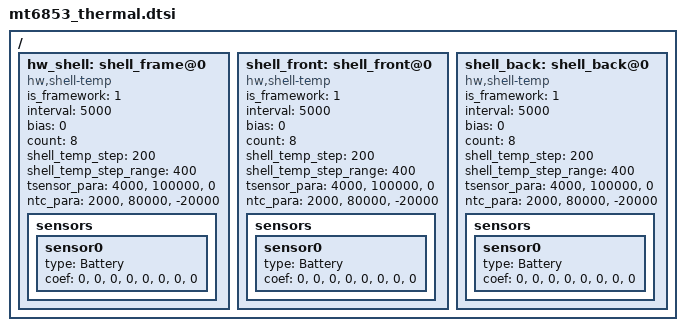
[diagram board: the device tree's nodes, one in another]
/{
	hw_shell: shell_frame@0 {
		compatible = "hw,shell-temp";
		is_framework = <1>;
		interval = <5000>;
		bias = <0>;
		count = <8>;
		shell_temp_step = <200>;
		shell_temp_step_range = <400>;
		tsensor_para = "4000","100000","0";
		ntc_para = "2000","80000","-20000";
		status = "ok";
		sensors {
			sensor0 {
				type = "Battery";
				coef = "0","0","0","0","0","0","0","0";
			};
		};
	};
	shell_front: shell_front@0 {
		compatible = "hw,shell-temp";
		is_framework = <1>;
		interval = <5000>;
		bias = <0>;
		count = <8>;
		shell_temp_step = <200>;
		shell_temp_step_range = <400>;
		tsensor_para = "4000","100000","0";
		ntc_para = "2000","80000","-20000";
		status = "ok";
		sensors {
			sensor0 {
				type = "Battery";
				coef = "0","0","0","0","0","0","0","0";
			};
		};
	};
	shell_back: shell_back@0 {
		compatible = "hw,shell-temp";
		is_framework = <1>;
		interval = <5000>;
		bias = <0>;
		count = <8>;
		shell_temp_step = <200>;
		shell_temp_step_range = <400>;
		tsensor_para = "4000","100000","0";
		ntc_para = "2000","80000","-20000";
		status = "ok";
		sensors {
			sensor0 {
				type = "Battery";
				coef = "0","0","0","0","0","0","0","0";
			};
		};
	};
};
